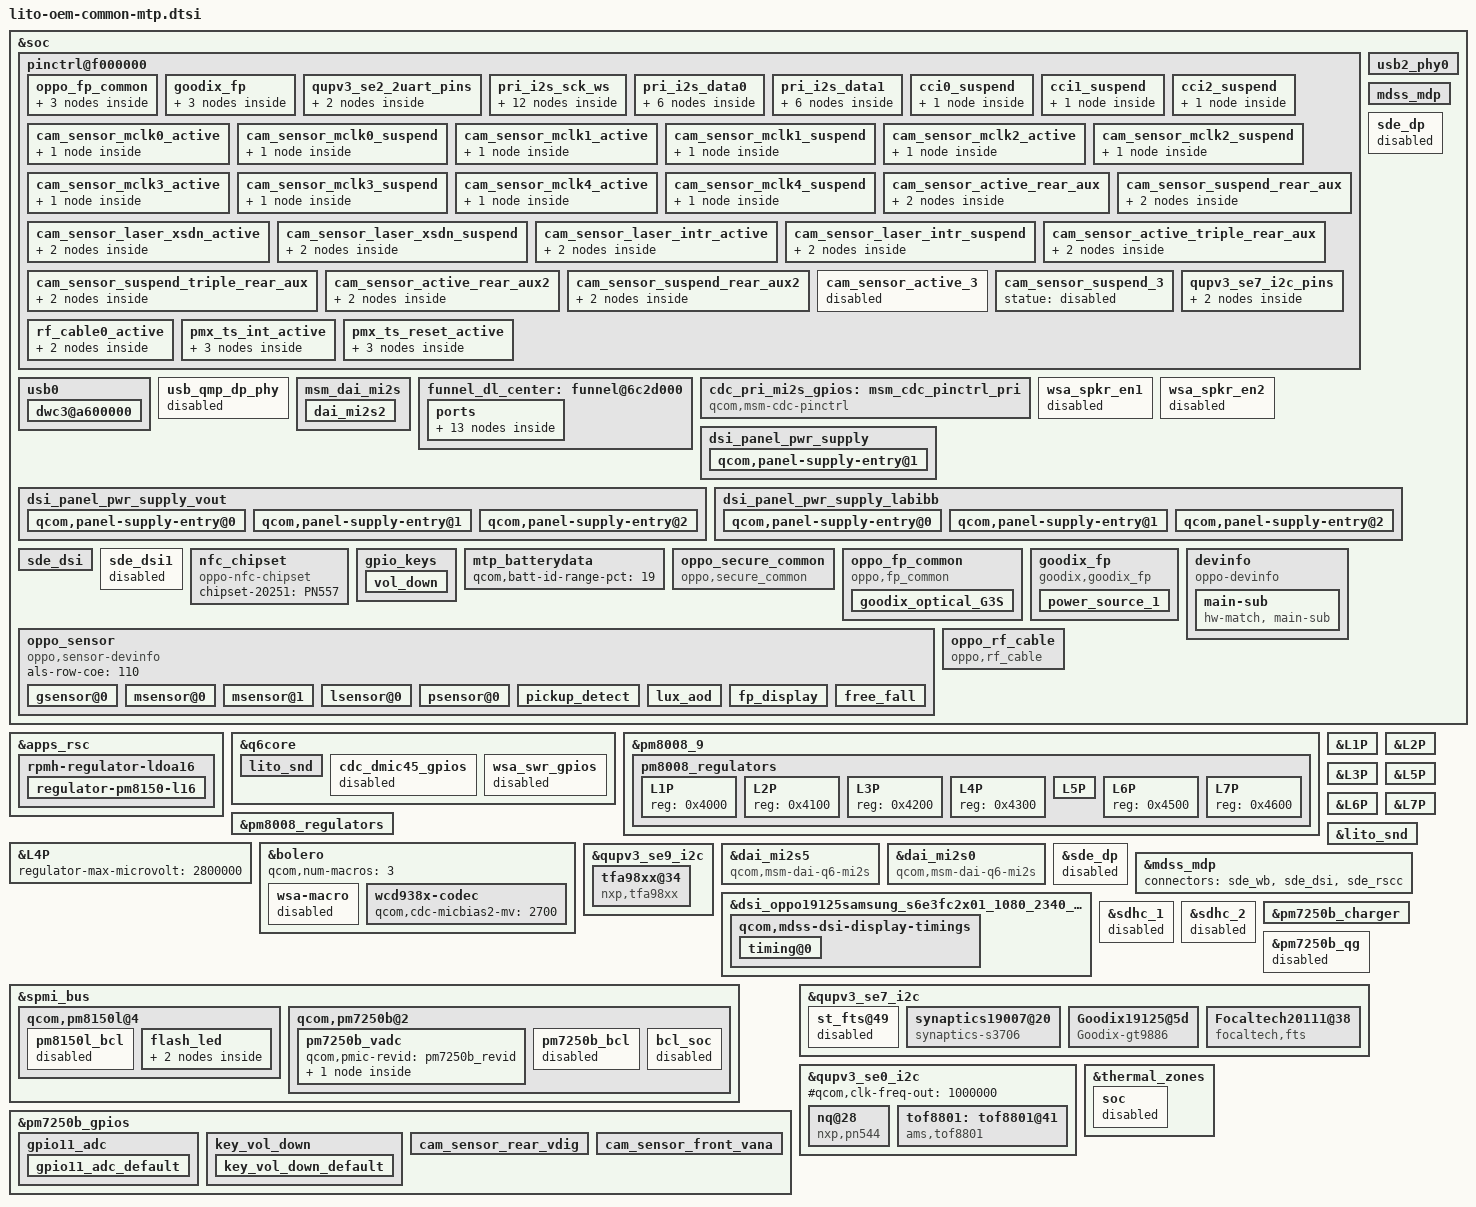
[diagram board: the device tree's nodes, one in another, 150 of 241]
#include <dt-bindings/msm/msm-bus-ids.h>
#include "oplus_charge.dtsi"
#include "camera/lito-camera.dtsi"
#include "camera/lito-camera-sensor-mtp.dtsi"

&soc {
        pinctrl@f000000 {
        //#ifdef /*VENDOR_EDIT*/
        /*Qijia.Zhou@BSP.Fingerprint.Basic,2020-08-01 add for fingerprint*/
        oppo_fp_common{
            gpio_id2_default: gpio_id2_default {
                mux {
                    pins = "gpio65";
                    function = "gpio";
                };
                config {
                    pins = "gpio65";
                    drive-strength = <2>;
                    bias-pull-up;
                    input-enable;
                };
            };
        };
        /*#ifdef VENDOR_EDIT Qijia.Zhou@Bsp.Fingerprint.Basic 2020-08-01 add for goodix fingerprint */
        goodix_fp{
            gpio_goodix_irq_default: gpio_goodix_irq_default {
                mux {
                    pins = "gpio112";
                    function = "gpio";
                };
                config {
                    pins = "gpio112";
                    drive-strength = <2>;
                    bias-disable;
                    input-enable;
                };
            };
        };
        //#endif /*VENDOR_EDIT*/

                qupv3_se2_2uart_pins {
                        qupv3_se2_2uart_sleep {
                                config {
                                        //#ifdef VENDOR_EDIT /* tongfeng.Huang@BSP.CHG.Basic, 2018/06/26, sjc Add for charging */
                                        input-enable;
                                        bias-disable;
                                        //#else
                                        ///bias-pull-down;
                                        //#endif
                                };
                        };
                };

                //#ifdef VENDOR_EDIT
                //Chunyu.xie@PSW.MM.AudioDriver.Machine, 2020/07/11, Add for primary MI2S gpio
                pri_i2s_sck_ws {
                        pri_i2s_sck_sleep: pri_i2s_sck_sleep {
                                mux {
                                        pins = "gpio49";
                                        function = "pri_mi2s";
                                };

                                config {
                                        pins = "gpio49";
                                        drive-strength = <2>;   /* 2 mA */
                                        bias-pull-down;
                                };
                        };

                        pri_i2s_sck_active: pri_i2s_sck_active {
                                mux {
                                        pins = "gpio49";
                                        function = "pri_mi2s";
                                };

                                config {
                                        pins = "gpio49";
                                        drive-strength = <4>;   /* 4 mA */
                                        bias-disable;
                                        output-high;
                                };
                        };

                        pri_i2s_ws_sleep: pri_i2s_ws_sleep {
                                mux {
                                        pins = "gpio50";
                                        function = "pri_mi2s_ws";
                                };

                                config {
                                        pins = "gpio50";
                                        drive-strength = <2>;   /* 2 mA */
                                        bias-pull-down;
                                };
                        };

                        pri_i2s_ws_active: pri_i2s_ws_active {
                                mux {
                                        pins = "gpio50";
                                        function = "pri_mi2s_ws";
                                };

                                config {
                                        pins = "gpio50";
                                        drive-strength = <4>;   /* 4 mA */
                                        bias-disable;
                                        output-high;
                                };
                        };
                };

                pri_i2s_data0 {
                        pri_i2s_data0_sleep: pri_i2s_data0_sleep {
                                mux {
                                        pins = "gpio51";
                                        function = "pri_mi2s";
                                };

                                config {
                                        pins = "gpio51";
                                        drive-strength = <2>;   /* 2 mA */
                                        bias-pull-down;
                                };
                        };

                        pri_i2s_data0_active: pri_i2s_data0_active {
                                mux {
                                        pins = "gpio51";
                                        function = "pri_mi2s";
                                };

                                config {
                                        pins = "gpio51";
                                        drive-strength = <4>;   /* 4 mA */
                                        bias-disable;
                                        output-high;
                                };
                        };
                };

                pri_i2s_data1 {
                        pri_i2s_data1_sleep: pri_i2s_data1_sleep {
                                mux {
                                        pins = "gpio52";
                                        function = "pri_mi2s";
                                };

                                config {
                                        pins = "gpio52";
                                        drive-strength = <2>;   /* 2 mA */
                                        bias-pull-down;
                                };
                        };

                        pri_i2s_data1_active: pri_i2s_data1_active {
                                mux {
                                        pins = "gpio52";
                                        function = "pri_mi2s";
                                };

                                config {
                                        pins = "gpio52";
                                        drive-strength = <4>;   /* 4 mA */
                                        bias-disable;
                                        output-high;
                                };
                        };
                };
                //#endif /* VENDOR_EDIT */

                cci0_suspend {
                        config {
/*#ifdef VENDOR_EDIT */
/* yufeng@camera.driver. 2019/10/22 */
                                //bias-pull-down; /* PULL DOWN */
                                bias-disable;
                                output-low;
/*endif*/
                        };
                };

                cci1_suspend {
                        config {
/*#ifdef VENDOR_EDIT */
/* yufeng@camera.driver. 2019/10/22 */
                                //bias-pull-down; /* PULL DOWN */
                                bias-disable;
                                output-low;
/*endif*/
                        };
                };

                cci2_suspend {
                        config {
/*#ifdef VENDOR_EDIT */
/* yufeng@camera.driver. 2019/10/22 */
                                //bias-pull-down; /* PULL DOWN */
                                bias-disable;
                                output-low;
/*endif*/
                        };
                };

                /* Camera GPIOs  CCI*/
                cam_sensor_mclk0_active {
                        config {
/*#ifdef VENDOR_EDIT */
/* yangsen@camera.driver. 2020/06/24 */
                                drive-strength = <6>; /* 2 MA */
/*endif*/
                        };
                };

                cam_sensor_mclk0_suspend {
                        config {
/*#ifdef VENDOR_EDIT */
/* yangsen@camera.driver. 2020/06/24 */
                                drive-strength = <6>; /* 2 MA */
/*endif*/
                        };
                };

                cam_sensor_mclk1_active {
                        config {
/*#ifdef VENDOR_EDIT */
/* yangsen@camera.driver. 2020/06/24 */
                                drive-strength = <6>; /* 2 MA */
/*endif*/
                        };
                };

                cam_sensor_mclk1_suspend {
                        config {
/*#ifdef VENDOR_EDIT */
/* yangsen@camera.driver. 2020/06/24 */
                                drive-strength = <6>; /* 2 MA */
/*endif*/
                        };
                };

                cam_sensor_mclk2_active {
                        config {
/*#ifdef VENDOR_EDIT */
/* yangsen@camera.driver. 2020/06/24 */
                                drive-strength = <6>; /* 2 MA */
/*endif*/
                        };
                };

                cam_sensor_mclk2_suspend {
                        config {
/*#ifdef VENDOR_EDIT */
/* yangsen@camera.driver. 2020/06/24 */
                                drive-strength = <6>; /* 2 MA */
/*endif*/
                        };
                };

                cam_sensor_mclk3_active {
                        config {
/*#ifdef VENDOR_EDIT */
/* yangsen@camera.driver. 2020/06/24 */
                                drive-strength = <6>; /* 2 MA */
/*endif*/
                        };
                };

                cam_sensor_mclk3_suspend {
                        config {
/*#ifdef VENDOR_EDIT */
/* yangsen@camera.driver. 2020/06/24 */
                                drive-strength = <6>; /* 2 MA */
/*endif*/
                        };
                };

                cam_sensor_mclk4_active {
                        config {
/*#ifdef VENDOR_EDIT */
/* yangsen@camera.driver. 2020/06/24 */
                                drive-strength = <6>; /* 2 MA */
/*endif*/
                        };
                };

                cam_sensor_mclk4_suspend {
                        config {
/*#ifdef VENDOR_EDIT */
/* yangsen@camera.driver. 2020/06/24 */
                                drive-strength = <6>; /* 2 MA */
/*endif*/
                        };
                };

                cam_sensor_active_rear_aux {
                        /* RESET REARAUX,DVDD ELDO */
                        mux {
                                pins = "gpio21", "gpio71";
                        };

                        config {
                                pins = "gpio21", "gpio71";
                        };
                };

                cam_sensor_suspend_rear_aux {
                        /* RESET REARAUX,DVDD ELDO */
                        mux {
                                pins = "gpio21", "gpio71";
                        };

                        config {
                                pins = "gpio21", "gpio71";
                        };
                };

            cam_sensor_laser_xsdn_active: cam_sensor_laser_xsdn_active {
            /* cam_sensor_laser_xsdn_active */
            mux {
                pins = "gpio128";
                function = "gpio";
            };

            config {
                pins = "gpio128";
                bias-disable; /* No PULL */
                drive-strength = <2>; /* 2 MA */
            };
        };

        cam_sensor_laser_xsdn_suspend: cam_sensor_laser_xsdn_suspend {
            /* cam_sensor_laser_xsdn_suspend  */
            mux {
                pins = "gpio128";
                function = "gpio";
            };

            config {
                pins = "gpio128";
                bias-pull-down; /* PULL DOWN */
                drive-strength = <2>; /* 2 MA */
                output-low;
            };
        };

        cam_sensor_laser_intr_active:cam_sensor_laser_intr_active {
            /* RESET REAR2 */
            mux {
                pins = "gpio5";
                function = "gpio";
            };

            config {
                pins = "gpio5";
                bias-disable; /* No PULL */
                drive-strength = <2>; /* 2 MA */
            };
        };

        cam_sensor_laser_intr_suspend: cam_sensor_laser_intr_suspend {
            /* RESET REAR2 */
            mux {
                pins = "gpio5";
                function = "gpio";
            };

            config {
                pins = "gpio5";
                bias-pull-down; /* PULL DOWN */
                drive-strength = <2>; /* 2 MA */
                output-low;
            };
        };

                cam_sensor_active_triple_rear_aux {
                        mux {
                                pins = "gpio23", "gpio70";
                        };

                        config {
                                pins = "gpio23", "gpio70";
                        };
                };

                cam_sensor_suspend_triple_rear_aux {
                        mux {
                                pins = "gpio23", "gpio70";
                        };

                        config {
                                pins = "gpio23", "gpio70";
                        };
                };

                cam_sensor_active_rear_aux2 {
                        mux {
                                pins = "gpio29", "gpio51";
                        };

                        config {
                                pins = "gpio29", "gpio51";
                        };
                };

                cam_sensor_suspend_rear_aux2 {
                        mux {
                                pins = "gpio29", "gpio51";
                        };

                        config {
                                pins = "gpio29", "gpio51";
                        };
                };

                cam_sensor_active_3 {
                        status = "disabled";
                };

                cam_sensor_suspend_3 {
                        statue = "disabled";
                };

                /* SE 7 pin mappings */
                qupv3_se7_i2c_pins {
                        qupv3_se7_i2c_sleep {
                                config {
                                        //#ifdef VENDOR_EDIT
                                        //Zengpeng.Chen@BSP.TP.Function 2019-08-08 add for set i2c bus line as input
                                        input-enable;
                                        //#endif//VENDOR_EDIT
                                };
                        };
                };

		//#ifdef VENDOR_EDIT
		/* Fuchun.Liao@BSP.CHG.Basic 2018/11/27 modify for rf-cable */
		rf_cable0_active: rf_cable0_active {
			mux {
				pins = "gpio90";
				function = "gpio";
			};
			config {
				pins = "gpio90";
				drive-strength = <2>;
				input-enable;
				bias-pull-up;
			};
		};
		//#endif /* VENDOR_EDIT */ 

                //#ifdef VENDOR_EDIT
                //Zengpeng.Chen@PSW.BSP.TP, 2020-04-22 add for touch gpio setting
                pmx_ts_int_active {
                        ts_int_active: ts_int_active {
                                mux {
                                        pins = "gpio9";
                                        function = "gpio";
                                };

                                config {
                                        pins = "gpio9";
                                        drive-strength = <2>;
                                        bias-disable;
                                };
                        };
                };

                pmx_ts_reset_active {
                        ts_reset_active: ts_reset_active {
                                mux {
                                        pins = "gpio8";
                                        function = "gpio";
                                };

                                config {
                                        pins = "gpio8";
                                        drive-strength = <2>;
                                        bias-disable;
                                        output-low;
                                };
                        };
                };
                //#endif
        };
};

&apps_rsc {
	rpmh-regulator-ldoa16 {
		regulator-pm8150-l16 {
			//#ifdef VENDOR_EDIT
			//LiPing-m@PSW.MM.Display.LCD 2018-10-21 Modity for lcd
			regulator-min-microvolt = <3000000>;
			qcom,init-voltage = <3000000>;
			//#endif
		};
	};
};

&soc {
        usb0 {
//#ifndef VENDOR_EDIT
//Kun.Zhang@BSP.CHG.Basic  2019/11/22  Modify for mtp/otg speed 
                //qcom,core-clk-rate = <133333333>;
//#else
                qcom,core-clk-rate = <200000000>;
//#endif

                qcom,msm-bus,vectors-KBps =
                        /*  suspend vote */
                        <MSM_BUS_MASTER_USB3 MSM_BUS_SLAVE_EBI_CH0 0 0>,
                        <MSM_BUS_MASTER_USB3 MSM_BUS_SLAVE_IPA_CFG 0 0>,
                        <MSM_BUS_MASTER_AMPSS_M0 MSM_BUS_SLAVE_USB3 0 0>,

                        /*  nominal vote */
//#ifndef VENDOR_EDIT
//Kun.Zhang@BSP.CHG.Basic  2019/11/22  Modify for mtp/otg speed 
                        //<MSM_BUS_MASTER_USB3
                                //MSM_BUS_SLAVE_EBI_CH0 1000000 2500000>,
                        //<MSM_BUS_MASTER_USB3 MSM_BUS_SLAVE_IPA_CFG 0 2400>,
                        //<MSM_BUS_MASTER_AMPSS_M0 MSM_BUS_SLAVE_USB3 0 40000>,
//#else
                        <MSM_BUS_MASTER_USB3
                                MSM_BUS_SLAVE_EBI_CH0 2500000 2500000>,
                        <MSM_BUS_MASTER_USB3 MSM_BUS_SLAVE_IPA_CFG 2400 2400>,
                        <MSM_BUS_MASTER_AMPSS_M0 MSM_BUS_SLAVE_USB3 40000 40000>,
//#endif

                        /*  svs vote */
//#ifndef VENDOR_EDIT
//Kun.Zhang@BSP.CHG.Basic  2019/11/22  Modify for mtp/otg speed 
                        //<MSM_BUS_MASTER_USB3
                                //MSM_BUS_SLAVE_EBI_CH0 240000 700000>,
                        //<MSM_BUS_MASTER_USB3 MSM_BUS_SLAVE_IPA_CFG 0 2400>,
                        //<MSM_BUS_MASTER_AMPSS_M0 MSM_BUS_SLAVE_USB3 0 40000>,
//#else
                        <MSM_BUS_MASTER_USB3
                                MSM_BUS_SLAVE_EBI_CH0 2500000 2500000>,
                        <MSM_BUS_MASTER_USB3 MSM_BUS_SLAVE_IPA_CFG 2400 2400>,
                        <MSM_BUS_MASTER_AMPSS_M0 MSM_BUS_SLAVE_USB3 40000 40000>,
//#endif

                        /*  min vote */
                        <MSM_BUS_MASTER_USB3 MSM_BUS_SLAVE_EBI_CH0 1 1>,
                        <MSM_BUS_MASTER_USB3 MSM_BUS_SLAVE_IPA_CFG 1 1>,
                        <MSM_BUS_MASTER_AMPSS_M0 MSM_BUS_SLAVE_USB3 1 1>;

                dwc3@a600000 {
//#ifndef VENDOR_EDIT
//Kun.Zhang@BSP.CHG.Basic  2019/09/25  Delete for usb 2.0
                        //usb-phy = <&usb2_phy0>, <&usb_qmp_dp_phy>;
//#else
                        usb-phy = <&usb2_phy0>, <&usb_nop_phy>;
//#endif

//#ifdef VENDOR_EDIT
//Kun.Zhang@BSP.CHG.Basic  2019/11/22  add for mtp/otg speed 
                        xhci-imod-value = <160>;
                        qcom,pm-qos-latency= <62>;
//#endif

//#ifndef VENDOR_EDIT
//Kun.Zhang@BSP.CHG.Basic  2019/09/25  Modify for usb 2.0
                        //maximum-speed = "super-speed";
//#else
                        maximum-speed = "high-speed";
//#endif
                };
        };

        usb2_phy0 {
//#ifndef VENDOR_EDIT
//Kun.Zhang@BSP.CHG.Basic  2019/09/25  Delete for usb eye parameter
                //qcom,param-override-seq = <0x43 0x70>;
//#else
                qcom,param-override-seq = <0x07 0x6c
                                                                  0x0f 0x70
                                                                  0x04 0x74
                                                                  0x0f 0x78>;
//#ifdef VENDOR_EDIT
//Jacky.Zhuo@BSP.CHG.Basic  2020/04/27  Add for host mode eye diagram
                qcom,param-override-seq-host = <0x07 0x6c
                                                                  0x0f 0x70
                                                                  0x04 0x74
                                                                  0x0f 0x78>;
//#endif
//#endif
        };

        usb_qmp_dp_phy {
//#ifndef VENDOR_EDIT
//Kun.Zhang@BSP.CHG.Basic  2019/09/25  Modify for usb 2.0
                //status = "ok";
//#else
                status = "disabled";
//endif
        };
};

&soc {
	msm_dai_mi2s {
		dai_mi2s2 {
			qcom,msm-mi2s-rx-lines = <0>;
			qcom,msm-mi2s-tx-lines = <3>;
		};
	};
};

&soc {
	funnel_dl_center: funnel@6c2d000 {
		ports {
			port@1 {
				reg = <0>;
			};

			port@2 {
				reg = <0>;
			};

			port@3 {
				reg = <0>;
			};

			port@4 {
				reg = <0>;
			};

			port@5 {
				reg = <0>;
			};

			port@6 {
				reg = <0>;
			};

			port@7 {
				reg = <0>;
			};

			port@8 {
				reg = <0>;
			};

			port@9 {
				reg = <0>;
			};

			port@10 {
				reg = <0>;
			};

			port@11 {
				reg = <0>;
			};

			port@12 {
				reg = <0>;
			};

			port@13 {
				reg = <0>;
			};
		};
	};
};

&q6core {
        lito_snd {
                //#ifndef VENDOR_EDIT
                //Chunyu.xie@PSW.MM.AudioDriver.Machine, 2020/07/11, Modify for MI2S
                //qcom,mi2s-audio-intf = <0>;
                //qcom,auxpcm-audio-intf = <0>;
                //qcom,tdm-audio-intf = <0>;
                //#else /* VENDOR_EDIT */
                qcom,mi2s-audio-intf = <1>;
                qcom,auxpcm-audio-intf = <1>;
                qcom,tdm-audio-intf = <1>;
                //#endif /* VENDOR_EDIT */
        };
};

&pm8008_9 {
	pm8008_regulators {
		L1P {
			reg =  /bits/ 16 <0x4000>;
		};

		L2P {
			reg =  /bits/ 16 <0x4100>;
		};

		L3P {
			reg =  /bits/ 16 <0x4200>;
		};

		L4P {
			reg =  /bits/ 16 <0x4300>;
		};

		L5P {
			reg =  /bits/ 16 <0x4400>;
/*#ifdef VENDOR_EDIT */
/* yufeng@camera.driver. 2019/04/03 */
			qcom,min-dropout-voltage = <200000>;
/*endif*/
		};

		L6P {
			reg =  /bits/ 16 <0x4500>;
		};

		L7P {
			reg =  /bits/ 16 <0x4600>;
		};
	};
};

&pm8008_regulators {
/* yufeng@camera.driver. 201/07/11 */
        vdd_l5-supply = <&S5A>;
        vdd_l6-supply = <&BOB>;
        vdd_l7-supply = <&BOB>;
};

&L1P {
/*#ifdef VENDOR_EDIT */
/* yangsen@camera.driver. 2020/06/24 */
        regulator-min-microvolt = <950000>;
        regulator-max-microvolt = <1150000>;
        qcom,min-dropout-voltage = <100000>;
/*endif */
};

&L2P {
/*#ifdef VENDOR_EDIT */
/* yangsen@camera.driver. 2020/06/24 */
        regulator-min-microvolt = <1200000>;
        regulator-max-microvolt = <1200000>;
        qcom,min-dropout-voltage = <100000>;
/*endif */
};

&L3P {
        regulator-min-microvolt = <2800000>;
        regulator-max-microvolt = <2800000>;
/*#ifdef VENDOR_EDIT */
/* yangsen@camera.driver. 2020/06/24 */
        //qcom,min-dropout-voltage = <136000>;
/*endif */
};

&L4P {
/*#ifdef VENDOR_EDIT */
/* yangsen@camera.driver. 2020/06/24 */
        regulator-max-microvolt = <2800000>;
        //qcom,min-dropout-voltage = <160000>;
/*endif */
};

&L5P {
/*#ifdef VENDOR_EDIT */
/* yangsen@camera.driver. 2020/06/24 */
        regulator-min-microvolt = <1800000>;
        regulator-max-microvolt = <1800000>;
        //qcom,min-dropout-voltage = <300000>;
/*endif */
};

&L6P {
/*#ifdef VENDOR_EDIT */
/* yangsen@camera.driver. 2020/06/24 */
        regulator-min-microvolt = <2800000>;
        regulator-max-microvolt = <2800000>;
        //qcom,min-dropout-voltage = <184000>;
/*endif */
};

&L7P {
/*#ifdef VENDOR_EDIT */
/* yangsen@camera.driver. 2020/06/24 */
        regulator-min-microvolt = <2900000>;
        regulator-max-microvolt = <2900000>;
        //qcom,min-dropout-voltage = <200000>;
/*endif */
};

&soc {
        mdss_mdp {
                clock-rate = <0 0 0 0 300000000 19200000 200000000
                                                200000000>;
        };

        sde_dp {
//#ifdef VENDOR_EDIT
//Kun.Zhang@BSP.CHG.Basic  2019/09/25  add for usb 2.0
                status = "disabled";
//#endif
        };
};

&bolero {
        //#ifndef VENDOR_EDIT
        //chunyu.xie@PSW.MM.AudioDriver.Machine, 2020/07/03, Modify for audio
        //qcom,num-macros = <4>;
        //#else /* VENDOR_EDIT */
        qcom,num-macros = <3>;
        //#endif /* VENDOR_EDIT */

        wsa-macro {
                //#ifdef VENDOR_EDIT
                //Chunyu.xie@PSW.MM.AudioDriver.Machine, 2020/07/11, Add for disable wsa
                status = "disabled";
                //#endif /* VENDOR_EDIT */
        };

        wcd938x-codec {
                //#ifdef VENDOR_EDIT
                //Chunyu.xie@PSW.MM.AudioDriver.Codec.AD113, 2020/07/11, Modify for change to 2.7V
                //qcom,cdc-micbias2-mv = <1800>;
                //#else /* VENDOR_EDIT */
                qcom,cdc-micbias2-mv = <2700>;
                //#endif /* VENDOR_EDIT */
        };
};

&lito_snd {
        qcom,audio-routing =
                "AMIC1", "MIC BIAS1",
                "MIC BIAS1", "Analog Mic1",
                "AMIC2", "MIC BIAS2",
                "MIC BIAS2", "Analog Mic2",
                "AMIC3", "MIC BIAS3",
                "MIC BIAS3", "Analog Mic3",
                "AMIC4", "MIC BIAS3",
                "MIC BIAS3", "Analog Mic4",
                //#ifdef OPLUS_ARCH_EXTENDS
                //Nan.Zhong@MULTIMEDIA.AUDIODRIVER.MACHINE, 2020/07/30, Modify for oplus extend aduio config
                //"AMIC5", "MIC BIAS4",
                //"MIC BIAS4", "Analog Mic5",
                //#else
                "AMIC5", "MIC BIAS3",
                "MIC BIAS3", "Analog Mic5",
                //#endif OPLUS_ARCH_EXTENDS
                //#ifndef VENDOR_EDIT
                //Chunyu.xie@PSW.MM.AudioDriver.Machine, 2020/07/11, Modify for msm dmic
                /*
                "TX DMIC0", "MIC BIAS3",
                "MIC BIAS3", "Digital Mic0",
                "TX DMIC1", "MIC BIAS3",
                "MIC BIAS3", "Digital Mic1",
                "TX DMIC2", "MIC BIAS1",
                "MIC BIAS1", "Digital Mic2",
                "TX DMIC3", "MIC BIAS1",
                "MIC BIAS1", "Digital Mic3",
                "TX DMIC4", "MIC BIAS4",
                "MIC BIAS4", "Digital Mic4",
                "TX DMIC5", "MIC BIAS4",
                "MIC BIAS4", "Digital Mic5",
                */
                //#else
                "TX DMIC0", "MIC BIAS1",
                "MIC BIAS1", "Digital Mic0",
                "TX DMIC1", "MIC BIAS1",
                "MIC BIAS1", "Digital Mic1",
                "TX DMIC2", "MIC BIAS3",
                "MIC BIAS3", "Digital Mic2",
                "TX DMIC3", "MIC BIAS3",
                "MIC BIAS3", "Digital Mic3",
                "TX DMIC4", "MIC BIAS4",
                "MIC BIAS4", "Digital Mic4",
                "TX DMIC5", "MIC BIAS4",
                "MIC BIAS4", "Digital Mic5",
                //#endif /* VENDOR_EDIT */
                //#ifdef VENDOR_EDIT
                //Chunyu.xie@PSW.MM.AudioDriver.Machine, 2020/07/11, Add for wcd938x dmic
                //anc mic, bias4
                "DMIC3", "MIC BIAS4",
                "MIC BIAS4", "Digital Mic2",
                "DMIC4", "MIC BIAS4",
                "MIC BIAS4", "Digital Mic3",
                //main mic, bias1
                "DMIC5", "MIC BIAS1",
                "MIC BIAS1", "Digital Mic4",
                "DMIC6", "MIC BIAS1",
                "MIC BIAS1", "Digital Mic5",
                //sec mic, bias3
                "DMIC7", "MIC BIAS3",
                "MIC BIAS3", "Digital Mic6",
                "DMIC8", "MIC BIAS3",
                "MIC BIAS3", "Digital Mic7",
                //#endif /* VENDOR_EDIT */
                "IN1_HPHL", "HPHL_OUT",
                "IN2_HPHR", "HPHR_OUT",
                "IN3_AUX", "AUX_OUT",
                "TX SWR_ADC0", "ADC1_OUTPUT",
                "TX SWR_ADC1", "ADC2_OUTPUT",
                "TX SWR_ADC2", "ADC3_OUTPUT",
                "TX SWR_ADC3", "ADC4_OUTPUT",
                "TX SWR_DMIC0", "DMIC1_OUTPUT",
                "TX SWR_DMIC1", "DMIC2_OUTPUT",
                "TX SWR_DMIC2", "DMIC3_OUTPUT",
                "TX SWR_DMIC3", "DMIC4_OUTPUT",
                "TX SWR_DMIC4", "DMIC5_OUTPUT",
                "TX SWR_DMIC5", "DMIC6_OUTPUT",
                "TX SWR_DMIC6", "DMIC7_OUTPUT",
                "TX SWR_DMIC7", "DMIC8_OUTPUT",
                "WSA SRC0_INP", "SRC0",
                "WSA_TX DEC0_INP", "TX DEC0 MUX",
                "WSA_TX DEC1_INP", "TX DEC1 MUX",
                "RX_TX DEC0_INP", "TX DEC0 MUX",
                "RX_TX DEC1_INP", "TX DEC1 MUX",
                "RX_TX DEC2_INP", "TX DEC2 MUX",
                "RX_TX DEC3_INP", "TX DEC3 MUX",
                "SpkrLeft IN", "WSA_SPK1 OUT",
                "SpkrRight IN", "WSA_SPK2 OUT",
                "VA_AIF1 CAP", "VA_SWR_CLK",
                "VA_AIF2 CAP", "VA_SWR_CLK",
                "VA_AIF3 CAP", "VA_SWR_CLK",
                "VA MIC BIAS3", "Digital Mic0",
                "VA MIC BIAS3", "Digital Mic1",
                "VA MIC BIAS1", "Digital Mic2",
                "VA MIC BIAS1", "Digital Mic3",
                "VA MIC BIAS4", "Digital Mic4",
                "VA MIC BIAS4", "Digital Mic5",
                "VA DMIC0", "VA MIC BIAS3",
                "VA DMIC1", "VA MIC BIAS3",
                "VA DMIC2", "VA MIC BIAS1",
                "VA DMIC3", "VA MIC BIAS1",
                "VA DMIC4", "VA MIC BIAS4",
                "VA DMIC5", "VA MIC BIAS4",
                "VA SWR_ADC0", "VA_SWR_CLK",
                "VA SWR_ADC1", "VA_SWR_CLK",
                "VA SWR_ADC2", "VA_SWR_CLK",
                "VA SWR_ADC3", "VA_SWR_CLK",
                "VA SWR_MIC0", "VA_SWR_CLK",
                "VA SWR_MIC1", "VA_SWR_CLK",
                "VA SWR_MIC2", "VA_SWR_CLK",
                "VA SWR_MIC3", "VA_SWR_CLK",
                "VA SWR_MIC4", "VA_SWR_CLK",
                "VA SWR_MIC5", "VA_SWR_CLK",
                "VA SWR_MIC6", "VA_SWR_CLK",
                "VA SWR_MIC7", "VA_SWR_CLK",
                "VA SWR_ADC0", "ADC1_OUTPUT",
                "VA SWR_ADC1", "ADC2_OUTPUT",
                "VA SWR_ADC2", "ADC3_OUTPUT",
                "VA SWR_ADC3", "ADC4_OUTPUT",
                "VA SWR_MIC0", "DMIC1_OUTPUT",
                "VA SWR_MIC1", "DMIC2_OUTPUT",
                "VA SWR_MIC2", "DMIC3_OUTPUT",
                "VA SWR_MIC3", "DMIC4_OUTPUT",
                "VA SWR_MIC4", "DMIC5_OUTPUT",
                "VA SWR_MIC5", "DMIC6_OUTPUT",
                "VA SWR_MIC6", "DMIC7_OUTPUT",
                "VA SWR_MIC7", "DMIC8_OUTPUT";
        //#ifdef VENDOR_EDIT
        //Chunyu.xie@PSW.MM.AudioDriver.Machine, 2020/07/11, Add for MI2S gpio
        //for tfa98xx i2s
        qcom,pri-mi2s-gpios = <&cdc_pri_mi2s_gpios>;
        //#endif /* VENDOR_EDIT */

        //#ifndef VENDOR_EDIT
        //Chunyu.xie@PSW.MM.AudioDriver.Machine, 2020/07/11, Modify for disable wsa
        /*
        qcom,wsa-max-devs = <2>;
        qcom,wsa-devs = <&wsa881x_0211>, <&wsa881x_0212>,
                        <&wsa881x_0213>, <&wsa881x_0214>;
        qcom,wsa-aux-dev-prefix = "SpkrLeft", "SpkrRight",
                                  "SpkrLeft", "SpkrRight";
        */
        //#else /* VENDOR_EDIT */
        qcom,wsa-max-devs = <0>;
        //#endif /* VENDOR_EDIT */

        /* #ifdef VENDOR_EDIT */
        /* Chunyu.xie@PSW.MM.AudioDriver.HeadsetDet, 2020/07/11, Add for HeadsetDet. */
        qcom,msm-mbhc-hs-mic-max-threshold-mv = <2600>;
        qcom,msm-mbhc-hs-mic-min-threshold-mv = <75>;
        /* #endif VENDOR_EDIT */

        /* #ifdef VENDOR_EDIT */
        /* Chunyu.xie@PSW.MM.AudioDriver.HeadsetDet, 2020/07/11, Add for mbhc cross connection. */
        oppo,mbhc-check-cross-conn = <0>;
        /* #endif VENDOR_EDIT */
};

&q6core {
        cdc_dmic45_gpios {
                //#ifndef VENDOR_EDIT
                //Chunyu.xie@PSW.MM.AudioDriver.Machine, 2020/07/11, Add for disable dmic45
                //use lpi_gpio12/13 conflict with tfa98xx i2s pin
                status = "disabled";
                //#endif /* VENDOR_EDIT */
        };

        wsa_swr_gpios {
                //#ifdef VENDOR_EDIT
                //Chunyu.xie@PSW.MM.AudioDriver.Machine, 2020/07/11, Add for disable wsa
                status = "disabled";
                //#endif /* VENDOR_EDIT */
        };
};

&soc {
	//#ifdef VENDOR_EDIT
        //Chunyu.xie@PSW.MM.AudioDriver.Machine, 2020/07/11, Add for primary MI2S gpio
        cdc_pri_mi2s_gpios: msm_cdc_pinctrl_pri {
                compatible = "qcom,msm-cdc-pinctrl";
                pinctrl-names = "aud_active", "aud_sleep";
                pinctrl-0 = <&pri_i2s_sck_active &pri_i2s_ws_active
                             &pri_i2s_data0_active &pri_i2s_data1_active>;
                pinctrl-1 = <&pri_i2s_sck_sleep &pri_i2s_ws_sleep
                             &pri_i2s_data0_sleep &pri_i2s_data1_sleep>;
        };
        //#endif /* VENDOR_EDIT */

        wsa_spkr_en1 {
                //#ifdef VENDOR_EDIT
                //Chunyu.xie@PSW.MM.AudioDriver.Machine, 2020/07/11, Add for disable wsa
                status = "disabled";
                //#endif /* VENDOR_EDIT */
        };

        wsa_spkr_en2 {
                //#ifdef VENDOR_EDIT
                //Chunyu.xie@PSW.MM.AudioDriver.Machine, 2020/07/11, Add for disable wsa
                status = "disabled";
                //#endif /* VENDOR_EDIT */
        };
};

/* #ifdef VENDOR_EDIT */
/*Chunyu.xie@PSW.MM.AudioDriver.Codec, 2020/07/11, Add for audio codec*/
&qupv3_se9_i2c {
        status = "okay";
        tfa98xx@34 {
                compatible = "nxp,tfa98xx";
                reg = <0x34>;
                tfa9874_vdd-supply = <&pm8150_s4>;
                tfa98xx_fw_name = "tfa98xx_20111.cnt";
                tfa_min_range = <5000>;
                tfa_max_range = <7800>;
                reset-gpio = <&tlmm 58 0x00>;
                status = "okay";
        };
};
/* #endif VENDOR_EDIT */

/* #ifdef VENDOR_EDIT */
/*Chunyu.xie@PSW.MM.AudioDriver.Codec, 2020/07/11, Add for audio driver*/
//Add for tfa98xx
&dai_mi2s5 {
        compatible = "qcom,msm-dai-q6-mi2s";
        qcom,msm-dai-q6-mi2s-dev-id = <5>;
        qcom,msm-mi2s-rx-lines = <1>;
        qcom,msm-mi2s-tx-lines = <2>;
};

//Add for tfa98xx after T0
&dai_mi2s0 {
        compatible = "qcom,msm-dai-q6-mi2s";
        qcom,msm-dai-q6-mi2s-dev-id = <0>;
        qcom,msm-mi2s-rx-lines = <1>;
        qcom,msm-mi2s-tx-lines = <2>;
};
/* #endif VENDOR_EDIT */

/* #ifdef OPLUS_ARCH_EXTENDS */
/* Jianfeng.Qiu@MULTIMEDIA.AUDIODRIVER.MACHINE, 2020/07/20, Add for oplus extend aduio config */
#include "oplus-audio-extend.dtsi"
/* #endif OPLUS_ARCH_EXTENDS */

//#ifdef VENDOR_EDIT
/* Ling.Guo@PSW.MM.Display.LCD.Stability, 2019/06/28, add for 19125 lcd bringup */
#include "dsi-panel-oppo19125samsung-s6e3fc2x01-1080-2340-61fps.dtsi"
#include "dsi-panel-oppo19125samsung-ams641rw01-1080-2340.dtsi"
#include "dsi-panel-oppo19125samsung-ams644va04-1080-2400.dtsi"
#include "dsi-panel-oppo19101boe-nt37800-1080-2400-90fps.dtsi"
/*Song.Gao@PSW.MM.Display.LCD.Params,2020-02-23 add 19015 FHD+ samsung temp panel */
#include "dsi-panel-oppo19015samsung-ams644vk01-1080-2400.dtsi"
#include "dsi-panel-oppo19015samsung-ams643xf01-1080-2400.dtsi"
/*Xinyu.Zhao@PSW.MM.Display.LCD.Params,2020-08-08 add 20111 FHD+ samsung panel */
#include "dsi-panel-oppo20111samsung-ams643ye01-1080-2400.dtsi"
//#endif /*VENDOR_EDIT*/

&soc {
	dsi_panel_pwr_supply {
		qcom,panel-supply-entry@1 {
			qcom,supply-enable-load = <857000>;
			qcom,supply-disable-load = <0>;
			qcom,supply-post-on-sleep = <0>;
		};
	};

	dsi_panel_pwr_supply_vout: dsi_panel_pwr_supply_vout {
		#address-cells = <1>;
		#size-cells = <0>;

		qcom,panel-supply-entry@0 {
			reg = <0>;
			qcom,supply-name = "vddio";
			qcom,supply-min-voltage = <1800000>;
			qcom,supply-max-voltage = <1800000>;
			qcom,supply-enable-load = <62000>;
			qcom,supply-disable-load = <80>;
			qcom,supply-post-on-sleep = <20>;
		};

		qcom,panel-supply-entry@1 {
			reg = <1>;
			qcom,supply-name = "vdd";
			qcom,supply-min-voltage = <3000000>;
			qcom,supply-max-voltage = <3000000>;
			qcom,supply-enable-load = <857000>;
			qcom,supply-disable-load = <0>;
			qcom,supply-post-on-sleep = <0>;
		};

		qcom,panel-supply-entry@2 {
			reg = <2>;
			qcom,supply-name = "vout";
			qcom,supply-min-voltage = <1500000>;
			qcom,supply-max-voltage = <1510000>;
			qcom,supply-enable-load = <857000>;
			qcom,supply-disable-load = <0>;
			qcom,supply-post-on-sleep = <0>;
		};
	};

        dsi_panel_pwr_supply_labibb: dsi_panel_pwr_supply_labibb {
                #address-cells = <1>;
                #size-cells = <0>;

                qcom,panel-supply-entry@0 {
                        reg = <0>;
                        qcom,supply-name = "vddio";
                        qcom,supply-min-voltage = <1800000>;
                        qcom,supply-max-voltage = <1800000>;
                        qcom,supply-enable-load = <62000>;
                        qcom,supply-disable-load = <80>;
                        qcom,supply-post-on-sleep = <20>;
                };

                qcom,panel-supply-entry@1 {
                        reg = <1>;
                        qcom,supply-name = "lab";
                        qcom,supply-min-voltage = <4600000>;
                        qcom,supply-max-voltage = <6000000>;
                        qcom,supply-enable-load = <100000>;
                        qcom,supply-disable-load = <100>;
                };

                qcom,panel-supply-entry@2 {
                        reg = <2>;
                        qcom,supply-name = "ibb";
                        qcom,supply-min-voltage = <4600000>;
                        qcom,supply-max-voltage = <6000000>;
                        qcom,supply-enable-load = <100000>;
                        qcom,supply-disable-load = <100>;
                        qcom,supply-post-on-sleep = <20>;
                };
        };

	sde_dsi {
		vout-supply = <&L5P>;
		qcom,dsi-default-panel = <&dsi_oppo20111samsung_ams643ye01_1080_2400_cmd>;
	};

	sde_dsi1 {
                //#ifdef VENDOR_EDIT
                /* Ling.Guo@PSW.MM.Display.LCD.Stability, 2019/06/28, add for 19031 lcd bringup */
                status = "disable";
                //#endif /*VENDOR_EDIT*/
        };
};

&sde_dp {
//#ifdef VENDOR_EDIT
//Kun.Zhang@BSP.CHG.Basic  2019/09/25  add for usb 2.0
        status = "disabled";
//#endif
};

&mdss_mdp {
// pixeworks dual channel start
//#ifndef VENDOR_EDIT
//Kun.Zhang@BSP.CHG.Basic  2019/09/25  add for usb 2.0
        //connectors = <&sde_wb &sde_dsi &sde_dsi1 &sde_dp &sde_rscc>;
//#else
        connectors = <&sde_wb &sde_dsi &sde_rscc>;
//#endif
// pixeworks dual channel end
};

//#ifdef VENDOR_EDIT
/* Ling.Guo@PSW.MM.Display.LCD.Stability, 2019/06/28, add for 19125 lcd bringup */
&dsi_oppo19125samsung_s6e3fc2x01_1080_2340_cmd {
        qcom,ulps-enabled;
        qcom,dsi-select-clocks = "mux_byte_clk0", "mux_pixel_clk0",
                                "src_byte_clk0", "src_pixel_clk0",
                                "shadow_byte_clk0", "shadow_pixel_clk0";
        qcom,mdss-dsi-t-clk-post = <0x0E>;
        qcom,mdss-dsi-t-clk-pre = <0x35>;
        qcom,mdss-dsi-display-timings {
                timing@0{
                        qcom,mdss-dsi-panel-phy-timings = [00 14 05 05 1f 1e 05
                                05 03 02 04 00 12 15];

                        qcom,display-topology = <1 0 1>;
                        qcom,default-topology-index = <0>;
                };
        };
};
//#endif /*VENDOR_EDIT*/

&spmi_bus {
	qcom,pm8150l@4 {
		pm8150l_bcl {
//#ifdef VENDOR_EDIT
//Kun.Zhang@BSP.CHG.Basic  2019/12/27  Modify for disable bcl 
			status = "disabled";
//#endif
		};

		flash_led {
			pm8150l_flash2 {
				/*#ifdef VENDOR_EDIT */
				status = "ok";
				/*endif */
			};

			pm8150l_torch2 {
				/*#ifdef VENDOR_EDIT */
				status = "ok";
				/*endif */
			};
		};
	};
};

&spmi_bus {
        qcom,pm7250b@2 {
                pm7250b_vadc {
                        //#ifdef VENDOR_EDIT
                        //tongfeng.huang@psw.BSP.CHG. 2020.01.13. add for pmic adc error
                        qcom,pmic-revid = <&pm7250b_revid>;
                        //#endif
			/*xing.xiong@BSP.Kernel.Driver, 2019/09/10, Add for adc read for aboard*/
			board_id {
				reg = <ADC_GPIO1>;
				label = "board_id_vdata";
				qcom,ratiometric;
				qcom,pre-scaling = <1 1>;
			}; 
                };

                pm7250b_bcl {
//#ifdef VENDOR_EDIT
//Kun.Zhang@BSP.CHG.Basic  2019/12/27  Modify for disable bcl 
                        status = "disabled";
//#endif
                };

                bcl_soc {
//#ifdef VENDOR_EDIT
//Kun.Zhang@BSP.CHG.Basic  2019/12/27  Modify for disable bcl 
                        status = "disabled";
//#endif
                };
        };
};

&soc {
    //#ifdef OPLUS_FEATURE_CONNFCSOFT
    //#DengWeiwei@Connectivity.NFC.BASIC.228691, 2020/08/05, Modify for : RTCID:2896930 CON_NFC_SOFT
    nfc_chipset {
        compatible = "oppo-nfc-chipset";
        chipset-20251 = "PN557";
    };
    //#endif /* OPLUS_FEATURE_CONNFCSOFT */

	gpio_keys {
		//#ifdef VENDOR_EDIT
		//Fei.Mo@BSP.group 2018-09-01 Modity for vol key
		pinctrl-0 = <&key_vol_up_default &key_vol_down_default>;
		//#endif

		//#ifdef VENDOR_EDIT
		//Fei.Mo@BSP.group 2018-09-01 Add for vol key
		vol_down {
			label = "volume_down";
			gpios = <&pm7250b_gpios  3 GPIO_ACTIVE_LOW>;
			linux,input-type = <1>;
			linux,code = <KEY_VOLUMEDOWN>;
			gpio-key,wakeup;
			debounce-interval = <15>;
			linux,can-disable;
		};
		//#endif
	};

        mtp_batterydata {
//#ifndef VENDOR_EDIT
//Yichun.Chen@BSP.CHG.Basic  2018/05/10  Delete for use oppo battery
//              qcom,batt-id-range-pct = <15>;
//#else
        qcom,batt-id-range-pct = <19>;
//#endif
        };

        // #ifdef OPLUS_FEATURE_SECURITY_COMMON
        /* Ping.Liu@Bsp.Fingerprint.Secure 2019-10-16 add for secure proc */
        oppo_secure_common {
                compatible = "oppo,secure_common";
        };
        //#endif /* OPLUS_FEATURE_SECURITY_COMMON */

    //#ifdef VENDOR_EDIT /*VENDOR_EDIT*/
    /*Qijia.Zhou@BSP.Fingerprint.Basic,2020-08-01 add for fingerprint*/
    oppo_fp_common {
        compatible = "oppo,fp_common";
        oppo,fp_gpio_num = <1>; /* the gpio number of fingerprint id used */
        oppo,fp_gpio_0 = <&tlmm 65 0x0>;
        pinctrl-names = "default";
        pinctrl-0 = <&gpio_id2_default>;
        goodix_optical_G3S {
            oppo,fp-id = <1>; /* fp id mapping table */
            vendor-chip = <11>; /* please refer to the struct fp_vendor_t in oppo_fp_commmon.n */
            eng-menu = "-1,-1"; /* represents SNR, inclination test item in engineer menu, and 0/1 means off/on */
            chip-name = "G_OPTICAL_G3S";  /* /proc/fp_id, will be displayed in engineer menu  */
        };
    };

    /*Qijia.Zhou@BSP.Fingerprint.Basic,2020-08-01 add for goodix fingerprint*/
    goodix_fp {
        status = "ok";
        compatible = "goodix,goodix_fp";
        interrupt-parent = <&tlmm>;
        interrupts = <112 0>;
        power-mode = <1> ; /*please refer to the struct fp_power_mode_t in oppo_fp_commmon.n ,0: power mode not set, 1: ldo power, 2: gpio power, 3: auto power */
        ldo-supply = <&pm8150a_l9>; // pm660l_l5 for goodix_fp
        ldo-config = <3300000 3300000 150000>;
        gpio-power = <&pm8150_gpios 7 GPIO_ACTIVE_LOW>;
        goodix,gpio_irq = <&tlmm 112 0x1>;
        goodix,gpio_reset = <&tlmm 63 0x0>;
        pinctrl-names = "default";
        pinctrl-0 = <&gpio_goodix_irq_default>;
        notify_tpinfo_flag = <1>;
        power-num = <1> ;
        power_source_1 {
            power-mode = <1>;   /* 1 = ldo power, refer to oppo_fp_common.h*/
            power-name = "ldo";
            power-config = "ldo-config";
            delay-time = <0>;
        };
    };
    //#endif /*VENDOR_EDIT*/

        //#ifdef OPLUS_FEATURE_SENSOR
        /*tangjh@BSP.sensor, 2020/07/31, Add for sensor dts*/
        /*enum sensor_id { OPPO_ACCEL,OPPO_GYRO,OPPO_MAG,OPPO_LIGHT,OPPO_PROXIMITY,OPPO_SAR,OPPO_CT,OPPO_BAROMETER,SENSORS_NUM};*/
        oppo_sensor {
                compatible = "oppo,sensor-devinfo";
                als-row-coe = <110>;
                /*enum {LSM6DSM = 0x01, BMI160 = 0x02, LSM6DS3 = 0x04, BMI260 = 0x08};*/
                gsensor@0 {
                        sensor-name = <0x02>;//BMI160
                        sensor-direction = <7>;
                        sensor-index = <0>;//source num
                        sensor-type = <0>;//OPPO_ACCEL
                };
                /* enum {AKM0991X = 0x01, MMC5603 = 0x02};*/
                msensor@0 {
                        sensor-name = <0x01>;//AKM09918
                        sensor-direction = <0>;
                        sensor-index = <0>;
                        sensor-type = <2>;//OPPO_MAG
                        parameter-number= <18>;
                        soft-mag-parameter = <9837 0 643 1 68 1 643 1 10025 0 48 1 68 1 48 1 10183 0>;//e00 sign e01 sign...
                };
                msensor@1 {
                        sensor-name = <0x02>;//MMC5603
                        sensor-direction = <1>;
                        sensor-index = <1>;
                        sensor-type = <2>;//OPPO_MAG
                };
                /*enum {STK3A5X=0x01,TCS3701=0x02,TCS3408=0x04,STK326X};*/
                /*enum {NORMAL=0x01,UNDER_LCD=0x02,VIRTUAL_UNDER_LCD=0x03}*/
                lsensor@0 {
                        sensor-name = <0x08>;//stk326x
                        sensor-index = <0>;
                        sensor-type = <3>;//OPPO_ALS
                        bus-number = <5>;
                        irq-number = <111>;
                        als-type = <2>;//UNDER_LCD
                        is-unit-device = <1>;
                        is-als-dri = <1>;
                        als-factor = <110>;
                        is_als_initialed = <0>;
                        als_buffer_length = <8>;
                };
                psensor@0 {
                        sensor-name = <0x08>;//stk326x
                        sensor-index = <0>;
                        sensor-type = <4>;//OPPO_PROXIMITY
                        bus-number = <5>;
                        irq-number = <111>;
                        ps-cail-type = <1>;
                        ps-type = <1>;
                        is_ps_initialzed = <0>;
                };
                /*virtual sensor
                enum sensor_algo_id {
                        OPPO_PICKUP_DETECT,
                        OPPO_LUX_AOD,
                        OPPO_TP_GESTURE,
                        OPPO_FP_DISPLAY,
                        OPPO_FREE_FALL,
                        OPPO_CAMERA_PROTECT,
                        SENSOR_ALGO_NUM
                }*/
                pickup_detect {
                        sensor-type = <0>; //OPPO_PICKUP_DETECT
                        is-virtual-sensor;
                        is-need-prox = <1>;
                        prox-type = <0>; // 0 - proximity; 1 - proximity_fake
                };
                lux_aod {
                        sensor-type = <1>; //OPPO_LUX_AOD
                        is-virtual-sensor;
                        thrd-low = <12>;
                        thrd-high = <50>;
                        als-type = <1>; // 0 - wise_light; 1 - ambient_light
                };
                fp_display {
                        sensor-type = <3>; //OPPO_FP_DISPLAY
                        is-virtual-sensor;
                        prox-type = <0>; // 0 - proximity; 1 - proximity_fake
                };
                free_fall {
                        sensor-type = <4>; //OPPO_FREE_FALL
                        is-virtual-sensor;
                };
        };
        //#endif /*OPLUS_FEATURE_SENSOR*/

	/*xing.xiong@BSP.Kernel.Driver, 2019/09/10, Add for adc read for aboard*/
	devinfo {
		compatible = "oppo-devinfo";

		io-channels= <&pm7250b_vadc ADC_GPIO1>;
		io-channel-names= "vph_pwr_voltage_sub";
		pinctrl-names = "default";
		pinctrl-0 = <&gpio11_adc_default>;

		main-sub {
			compatible = "hw-match, main-sub";
			use_pmic_adc;
			adc_ranges = <0 80
						81 180
						181 300
						301 420
						421 550
						551 650
						651 760
						761 850
						851 850
						951 1050
						1051 1150
						1151 1300>;
			aboard-patterns = <0 0 1>;

			/*main board*/
			match-projects = <20111 20113 20251 20811>;
		};
	};

	/* Fuchun.Liao@BSP.CHG.Basic 2018/11/26 modify for oppo rf cable monitor */
        oppo_rf_cable {
                compatible = "oppo,rf_cable";
                interrupt-parent = <&tlmm>;
                rf_cable_support_num = <1>;
                rf,cable0-gpio = <&tlmm 90 0>;
                rf,cable-support-timer = <0>;
                pinctrl-names = "rf_cable_active";
                pinctrl-0 = <&rf_cable0_active>;
        };
	//#endif /* VENDOR_EDIT */
};

&pm7250b_gpios{
//#ifdef VENDOR_EDIT
//tongfeng.huang@BSP.CHG.Basic  2019/11/20  add for board-id adc
        gpio11_adc {
        gpio11_adc_default: gpio11_adc_default {
        pins = "gpio11"; /* GPIO 11 */
        function = "normal"; /* normal */
        bias-high-impedance; /* DISABLE GPIO11 for ADC*/
        };
    };
//#endif

	//#ifdef VENDOR_EDIT
	//Fei.Mo@BSP.group 2018-09-01 Add for vol key
	key_vol_down {
		key_vol_down_default: key_vol_down_default {
			pins = "gpio3";
			function = "normal";
			input-enable;
			bias-pull-up;
			power-source = <0>;
		};
	};
	//#endif

/*#ifdef VENDOR_EDIT */
/* yangsen@camera.driver. 2020/06/24, add for gpio of camera */
	cam_sensor_rear_vdig: cam_sensor_rear_vdig {
		pins = "gpio10";
		function = "normal";
		power-source = <0>;
		drive-push-pull;
		output-low;
	};
	cam_sensor_front_vana: cam_sensor_front_vana {
		pins = "gpio12";
		function = "normal";
		power-source = <0>;
		drive-push-pull;
		output-low;
	};
/*
	cam_sensor_rear2_vana: cam_sensor_rear2_vana {
		pins = "gpio2";
		function = "normal";
		power-source = <0>;
		output-low;
	};

*/
/*endif */
};

&sdhc_1 {
//#ifndef VENDOR_EDIT
//jason.wu@BSP.Storage.UFS 2020-8-12 this project has no emmc
//	status = "ok";
//#else
	status = "disabled";
//#endif
};

&sdhc_2 {
/* #ifndef VENDOR_EDIT */
/* Qijia.Zhou@BSP.Fingerprint.Basic 2020/08/03, remove for fingerprint power */
    /* vdd-supply = <&pm8150a_l9>; */
/* #endif VENDOR_EDIT */
//#ifndef VENDOR_EDIT
//jason.wu@BSP.Storage.UFS 2020-8-12 this project has no T card
//	status = "ok";
//#else
	status = "disabled";
//#endif
};

&pm7250b_charger {
        io-channels = <&pm7250b_vadc ADC_USB_IN_V_16>,
                      <&pm7250b_vadc ADC_USB_IN_I>,
                      <&pm7250b_vadc ADC_CHG_TEMP>,
//#ifdef VENDOR_EDIT /* tongfeng.Huang@BSP.CHG.Basic, 2016/12/26,  Add for charging chgID */
                          <&pm7250b_vadc ADC_GPIO3>,
                          <&pm7250b_vadc ADC_AMUX_THM4_PU2>,
//#endif
                      <&pm7250b_vadc ADC_DIE_TEMP>,
                      <&pm7250b_vadc ADC_AMUX_THM3_PU2>,
                      <&pm7250b_vadc ADC_SBUx>,
                      <&pm7250b_vadc ADC_VPH_PWR>,
                      <&pm7250b_vadc ADC_AMUX_THM1_PU2>;
        io-channel-names = "usb_in_voltage",
                           "usb_in_current",
                           "chg_temp",
//#ifdef VENDOR_EDIT /* Kun.Zhang@BSP.CHG.Basic, 2019/09/18,  Add for charging chgID */
                           "chgID_voltage_adc",
                           "usb_temp_l",
//#endif
                           "die_temp",
//#ifdef VENDOR_EDIT /* Kun.Zhang@BSP.CHG.Basic, 2019/09/18,  Add for charging usbtemp */
                           "usb_temp_r",
//#else
                           //"conn_temp",
//#endif
                           "sbux_res",
                           "vph_voltage",
                           "skin_temp";
};

&pm7250b_qg {
//#ifdef VENDOR_EDIT /* Kun.Zhang@BSP.CHG.Basic, 2019/09/18,  Remove for charging */
        status = "disabled";
//#else
        //status = "ok";
//#endif
};

&qupv3_se7_i2c {
        //#ifdef VENDOR_EDIT
        //wangkun@BSP.group 2019-06-28 add for enable i2c_7
	st_fts@49 {
		status = "disabled";
	};

        synaptics19007@20 {
                compatible = "synaptics-s3706";
                reg = <0x20>;
                chip-name = "S3706";

                /* Interrupt && Irq-gpio */
                interrupt-parent = <&tlmm>;
                interrupts = <9 0x2008>;

                /* Power Config */
                vdd_2v8-supply = <&pm8150_l13>;
                vcc_1v8-supply = <&pm8150a_l1>;
                vdd_2v8_volt = <3000000>;

                /* Other HW Resource */
                irq-gpio = <&tlmm 9 0x2008>;
                reset-gpio = <&tlmm 8 0x1>;
                pinctrl-names = "default";
                pinctrl-0 = <&ts_int_active &ts_reset_active>;

                touchpanel,max-num-support = <10>;
                touchpanel,tx-rx-num = <16 34>;
                touchpanel,panel-coords = <1080 2340>;
                touchpanel,display-coords = <1080 2340>;
                touchpanel,touchmajor-limit = <0 54>;

                /* SW Support Feature Control */
                black_gesture_support;
                fw_edge_limit_support;
                fw_corner_limit_support;
                pressure_report_support;
                //spurious_fingerprint_support;
                charger_pump_support;
                game_switch_support;
                face_detect_support;
                smart_gesture_support;
                fw_update_app_support;
                fingerprint_underscreen_support;
                rt155_fdreplace_rt59_support;
                report_120hz_support;
                /*
                 *Virtual Key Config:
                 *1:touchpanel,button-type: <virtualkey_type  supportted_button-map>
                 *virtualkey_type:
                 *Type 1: using board_properties
                 *Type 2: using same IC (button zone&& touch zone are seprate)
                 *Type 3: using diffrent IC (button zone&& touch zone are seprate)
                 *Type 4: No need of virtual key process
                 *supportted_button-map:select|menu|home|back
                 *
                 *2:touchpanel,button-map
                 *type (X1,Y1)(X2,Y2)(X3,Y3)(Width_X,Hight_Y)--Only when button-type is 0
                 */
                touchpanel,button-type = <4>;
                touchpanel.button-TRx = <0 0>;
        };
        //#endif

        //#ifdef VENDOR_EDIT
        //Zengpeng.Chen@BSP.TP.Function 2019-08-25 add for enable Goodix touch device
        Goodix19125@5d {
                compatible = "Goodix-gt9886";
                reg = <0x5d>;
                chip-name = "GT9886";

                /* Interrupt && Irq-gpio */
                interrupt-parent = <&tlmm>;
                interrupts = <9 0x2002>;

                /* Power Config */
                vdd_2v8-supply = <&pm8150_l13>;
                vcc_1v8-supply = <&pm8150a_l1>;
                vdd_2v8_volt = <3100000>;

                /* Other HW Resource */
                irq-gpio = <&tlmm 9 0x2002>;
                reset-gpio = <&tlmm 8 0x1>;
                pinctrl-names = "default";
                pinctrl-0 = <&ts_int_active &ts_reset_active>;

                vid_len = <2>;
                tp_type = <8>;
                // type of tp_dev ,TP-SAMSUNG = 8;
                platform_support_project = <20111 20113 20251 20811>;
                platform_support_project_dir = <19015 19015 19015 19015>;
                platform_support_project_commandline = "oppo19015samsung", "oppo19015samsung", "oppo19015samsung", "oppo19015samsung";

                touchpanel,max-num-support = <10>;
                touchpanel,tx-rx-num = <16 34>;
                touchpanel,panel-coords = <1080 2400>;
                touchpanel,display-coords = <1080 2400>;
                touchpanel,touchmajor-limit = <0 54>;

                /* SW Support Feature Control */
                register-is-16bit;
                black_gesture_support;
                fw_edge_limit_support;
                pressure_report_support;
                charger_pump_support;
                game_switch_support;
                smart_gesture_support;
                fw_update_app_support;
                fingerprint_underscreen_support;
                esd_handle_support;
                //new_set_irq_wake_support;
                //single_tap_support;
                /*
                 *Virtual Key Config:
                 *1:touchpanel,button-type: <virtualkey_type  supportted_button-map>
                 *virtualkey_type:
                 *Type 1: using board_properties
                 *Type 2: using same IC (button zone&& touch zone are seprate)
                 *Type 3: using diffrent IC (button zone&& touch zone are seprate)
                 *Type 4: No need of virtual key process
                 *supportted_button-map:select|menu|home|back
                 *
                 *2:touchpanel,button-map
                 *type (X1,Y1)(X2,Y2)(X3,Y3)(Width_X,Hight_Y)--Only when button-type is 0
                 */
                touchpanel,button-type = <4>;
                touchpanel.button-TRx = <0 0>;
        };

	Focaltech20111@38 {
		compatible = "focaltech,fts";
		reg = <0x38>;
		chip-name = "FT3518";

		/* Interrupt && Irq-gpio */
		interrupt-parent = <&tlmm>;
		interrupts = <9 0x2002>;

		/* Power Config */
		vdd_2v8-supply = <&pm8150_l13>;
		vcc_1v8-supply = <&pm8150a_l1>;
		vdd_2v8_volt = <3100000>;

		/* Other HW Resource */
		irq-gpio = <&tlmm 9 0x2002>;
		reset-gpio = <&tlmm 8 0x1>;
		pinctrl-names = "default";
		pinctrl-0 = <&ts_int_active &ts_reset_active>;

		vid_len = <2>;
		tp_type = <8>;
		// type of tp_dev ,TP-SAMSUNG = 8;
		platform_support_project = <20111 20113 20251 20811>;
		platform_support_project_dir = <20111 20111 20111 20811>;
		platform_support_project_commandline = "oppo20111samsung", "oppo20111samsung", "oppo20111samsung", "oppo20111samsung";
		platform_support_project_external_name = "BD368", "BD368", "BD368", "BD368";

		touchpanel,max-num-support = <10>;
		touchpanel,tx-rx-num = <16 34>;
		touchpanel,panel-coords = <1080 2400>;
		touchpanel,display-coords = <1080 2400>;
		touchpanel,touchmajor-limit = <0 54>;

		/* SW Support Feature Control */
		black_gesture_support;
		fw_edge_limit_support;
		pressure_report_support;
		charger_pump_support;
		game_switch_support;
		smart_gesture_support;
		fw_update_app_support;
		fingerprint_underscreen_support;
		headset_pump_support;
		irq_need_dev_resume_ok;
		//esd_handle_support;
		/*
		 *Virtual Key Config:
		 *1:touchpanel,button-type: <virtualkey_type  supportted_button-map>
		 *virtualkey_type:
		 *Type 1: using board_properties
		 *Type 2: using same IC (button zone&& touch zone are seprate)
		 *Type 3: using diffrent IC (button zone&& touch zone are seprate)
		 *Type 4: No need of virtual key process
		 *supportted_button-map:select|menu|home|back
		 *
		 *2:touchpanel,button-map
		 *type (X1,Y1)(X2,Y2)(X3,Y3)(Width_X,Hight_Y)--Only when button-type is 0
		 */
		touchpanel,button-type = <4>;
		touchpanel.button-TRx = <0 0>;
	};
        //#endif
};

&qupv3_se0_i2c {
       //#ifdef OPLUS_NFC_BRINGUP
       //DengWeiwei@CONNECTIVITY.NFC.HARDWARE.228691, 2020/08/03
       //Mod for NXP PN557 NFC GPIO
       /*status = "ok";
	qcom,clk-freq-out = <1000000>;
	#address-cells = <1>;
	#size-cells = <0>;
	nq@28 {
		compatible = "qcom,nq-nci";
		reg = <0x28>;
		qcom,nq-irq = <&tlmm 34 0x00>;
		qcom,nq-ven = <&tlmm 12 0x00>;
		qcom,nq-firm = <&tlmm 35 0x00>;
		qcom,nq-clkreq = <&tlmm 31 0x00>;
		interrupt-parent = <&tlmm>;
		interrupts = <34 0>;
		interrupt-names = "nfc_irq";
		pinctrl-names = "nfc_active", "nfc_suspend";
		pinctrl-0 = <&nfc_int_active &nfc_enable_active
				&nfc_clk_req_active>;
		pinctrl-1 = <&nfc_int_suspend &nfc_enable_suspend
				&nfc_clk_req_suspend>;
	};*/
       //#else /* OPLUS_NFC_BRINGUP */
	status = "ok";
	#qcom,clk-freq-out = <1000000>;
	#address-cells = <1>;
	#size-cells = <0>;
	nq@28 {
		compatible = "nxp,pn544";
		reg = <0x28>;
		nxp,pn544-irq = <&tlmm 34 0x00>;
		nxp,pn544-ven = <&tlmm 12 0x00>;
		nxp,pn544-fw-dwnld = <&tlmm 35 0x00>;
		qcom,nq-clkreq = <&tlmm 31 0x00>;
		interrupt-parent = <&tlmm>;
		interrupts = <34 0>;
		interrupt-names = "nfc_irq";
		pinctrl-names = "nfc_active", "nfc_suspend";
		pinctrl-0 = <&nfc_int_active &nfc_enable_active
				&nfc_clk_req_active>;
		pinctrl-1 = <&nfc_int_suspend &nfc_enable_suspend
				&nfc_clk_req_suspend>;
	};
       //#endif /*OPLUS_NFC_BRINGUP*/

    tof8801: tof8801@41 {
        compatible = "ams,tof8801";
        reg = <0x41>; /* x41 for HW, x39 for test chip */
        tof,tof_poll_period = <0xA>; /*poll period (100 usec)*/
        laser_vdd-supply = <&L6P>;
        pinctrl-names = "laser_default", "laser_suspend";
        pinctrl-0 = <&cam_sensor_laser_xsdn_active
                     &cam_sensor_laser_intr_active>;
        pinctrl-1 = <&cam_sensor_laser_xsdn_suspend
                     &cam_sensor_laser_intr_suspend>;

        interrupt-parent = <&tlmm>;
        enable-gpios = <&tlmm 128 0>;
    };
};

&thermal_zones {
	soc {
		//#ifdef VENDOR_EDIT
		//cuixiaogang@SH. 2019.11.30. disable low battery limit
		status="disabled";
		//#endif
	};
};
